# STM32L422 register map
File version: 1.0
CPU: CM4 r0p1, little endian, MPU, FPU, 4 interrupt priority bits
Registers are 32-bit, read-write, reset 0x0 unless marked. A register's access mark holds for its fields unless they carry their own. Offsets are from the block's base; [hi:lo] are bit positions; {n}, {i} and the like mark numbered series; 'fields as' and 'values as' point back to an identical list.

## DMA1 — Direct memory access controller
Base 0x40020000
Same registers: DMA2 0x40020400
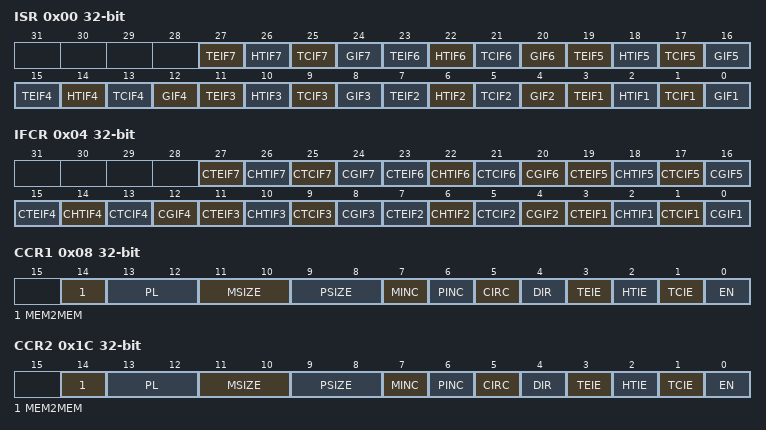
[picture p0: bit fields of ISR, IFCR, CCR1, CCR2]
0x00 ISR ro — interrupt status register
  [4n-1] TEIF{n} (n=1..7) — Channel x transfer error flag (x = 1 ..7)
  [4n-2] HTIF{n} (n=1..7) — Channel x half transfer flag (x = 1 ..7)
  [4n-3] TCIF{n} (n=1..7) — Channel x transfer complete flag (x = 1 ..7)
  [4n-4] GIF{n} (n=1..7) — Channel x global interrupt flag (x = 1 ..7)
0x04 IFCR wo — interrupt flag clear register
  [4n-1] CTEIF{n} (n=1..7) — Channel x transfer error clear (x = 1 ..7)
  [4n-2] CHTIF{n} (n=1..7) — Channel x half transfer clear (x = 1 ..7)
  [4n-3] CTCIF{n} (n=1..7) — Channel x transfer complete clear (x = 1 ..7)
  [4n-4] CGIF{n} (n=1..7) — Channel x global interrupt clear (x = 1 ..7)
0x08 CCR1 — channel x configuration register
  [14] MEM2MEM — Memory to memory mode
  [13:12] PL — Channel priority level
  [11:10] MSIZE — Memory size
  [9:8] PSIZE — Peripheral size
  [7] MINC — Memory increment mode
  [6] PINC — Peripheral increment mode
  [5] CIRC — Circular mode
  [4] DIR — Data transfer direction
  [3] TEIE — Transfer error interrupt enable
  [2] HTIE — Half transfer interrupt enable
  [1] TCIE — Transfer complete interrupt enable
  [0] EN — Channel enable
0x0C CNDTR1 — channel x number of data register
  [15:0] NDT — Number of data to transfer
0x10 CPAR1 — channel x peripheral address register
  [31:0] PA — Peripheral address
{0x0+0x14*i} CMAR{i} (i=1..7) — channel x memory address register
  [31:0] MA — Memory address
0x1C CCR2 — channel x configuration register
  fields as CCR1
0x20 CNDTR2 — channel x number of data register
  [15:0] NDT — Number of data to transfer
0x24 CPAR2 — channel x peripheral address register
  [31:0] PA — Peripheral address
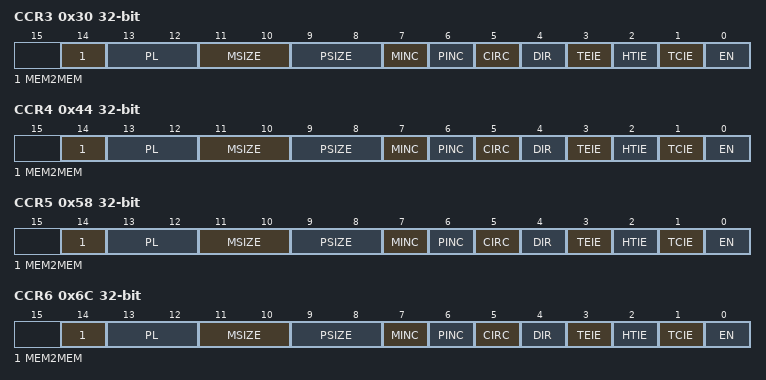
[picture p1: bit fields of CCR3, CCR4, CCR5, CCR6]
0x30 CCR3 — channel x configuration register
  fields as CCR1
0x34 CNDTR3 — channel x number of data register
  [15:0] NDT — Number of data to transfer
0x38 CPAR3 — channel x peripheral address register
  [31:0] PA — Peripheral address
0x44 CCR4 — channel x configuration register
  fields as CCR1
0x48 CNDTR4 — channel x number of data register
  [15:0] NDT — Number of data to transfer
0x4C CPAR4 — channel x peripheral address register
  [31:0] PA — Peripheral address
0x58 CCR5 — channel x configuration register
  fields as CCR1
0x5C CNDTR5 — channel x number of data register
  [15:0] NDT — Number of data to transfer
0x60 CPAR5 — channel x peripheral address register
  [31:0] PA — Peripheral address
0x6C CCR6 — channel x configuration register
  fields as CCR1
0x70 CNDTR6 — channel x number of data register
  [15:0] NDT — Number of data to transfer
0x74 CPAR6 — channel x peripheral address register
  [31:0] PA — Peripheral address
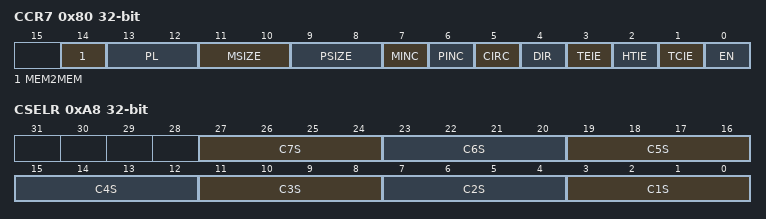
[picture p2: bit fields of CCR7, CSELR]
0x80 CCR7 — channel x configuration register
  fields as CCR1
0x84 CNDTR7 — channel x number of data register
  [15:0] NDT — Number of data to transfer
0x88 CPAR7 — channel x peripheral address register
  [31:0] PA — Peripheral address
0xA8 CSELR — channel selection register
  [4n-1:4n-4] C{n}S (n=1..7) — DMA channel {n} selection

## EXTI — External interrupt/event controller
Base 0x40010400
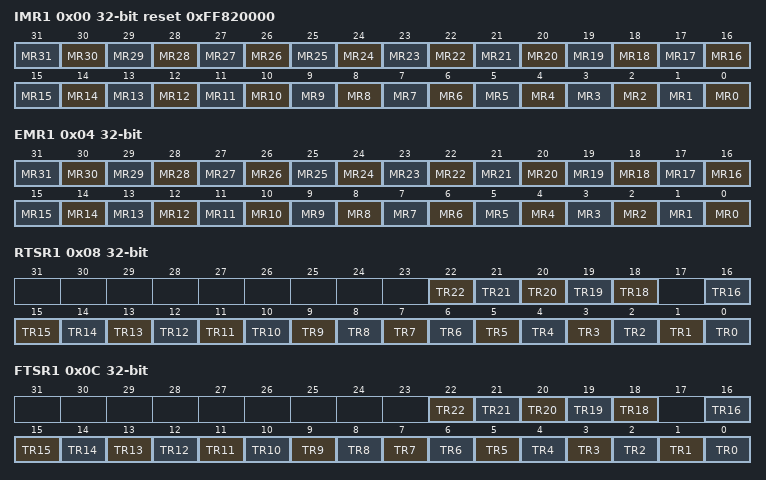
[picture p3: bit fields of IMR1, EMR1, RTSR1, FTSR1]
0x00 IMR1 reset 0xFF820000 — Interrupt mask register
  [n] MR{n} (n=0..31) — Interrupt Mask on line {n}
0x04 EMR1 — Event mask register
  [n] MR{n} (n=0..31) — Event Mask on line {n}
0x08 RTSR1 — Rising Trigger selection register
  [n] TR{n} (n=18..22) — Rising trigger event configuration of line {n}
  [n] TR{n} (n=0..16) — Rising trigger event configuration of line {n}
0x0C FTSR1 — Falling Trigger selection register
  [n] TR{n} (n=18..22) — Falling trigger event configuration of line {n}
  [n] TR{n} (n=0..16) — Falling trigger event configuration of line {n}
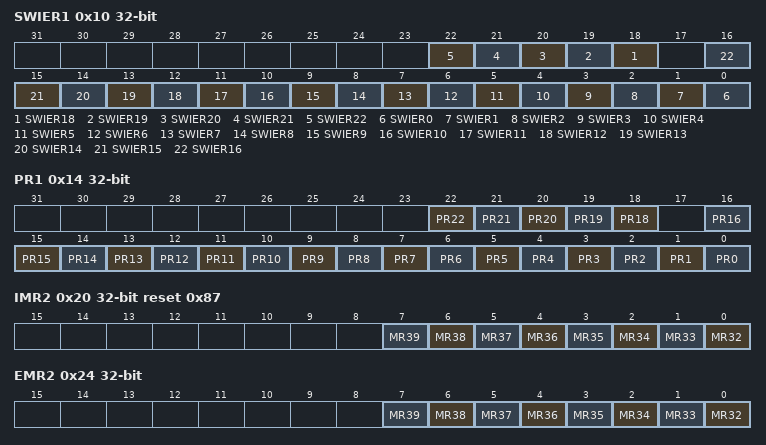
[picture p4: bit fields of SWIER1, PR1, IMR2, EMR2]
0x10 SWIER1 — Software interrupt event register
  [n] SWIER{n} (n=18..22) — Software Interrupt on line {n}
  [n] SWIER{n} (n=0..16) — Software Interrupt on line {n}
0x14 PR1 — Pending register
  [n] PR{n} (n=18..22) — Pending bit {n}
  [n] PR{n} (n=0..16) — Pending bit {n}
0x20 IMR2 reset 0x87 — Interrupt mask register
  [n-32] MR{n} (n=32..39) — Interrupt Mask on external/internal line {n}
0x24 EMR2 — Event mask register
  [n-32] MR{n} (n=32..39) — Event mask on external/internal line {n}
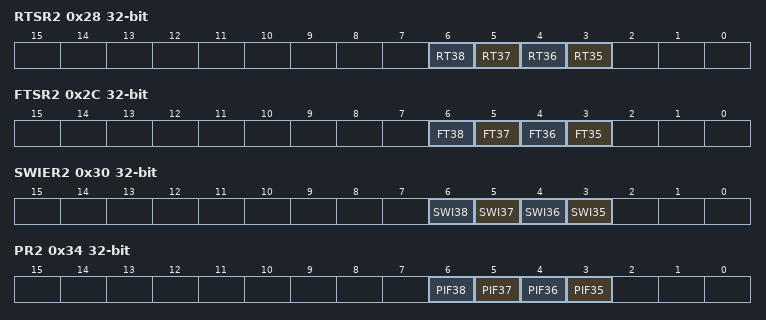
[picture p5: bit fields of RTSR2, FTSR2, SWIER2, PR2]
0x28 RTSR2 — Rising Trigger selection register
  [n-32] RT{n} (n=35..38) — Rising trigger event configuration bit of line {n}
0x2C FTSR2 — Falling Trigger selection register
  [n-32] FT{n} (n=35..38) — Falling trigger event configuration bit of line {n}
0x30 SWIER2 — Software interrupt event register
  [n-32] SWI{n} (n=35..38) — Software interrupt on line {n}
0x34 PR2 — Pending register
  [n-32] PIF{n} (n=35..38) — Pending interrupt flag on line {n}
